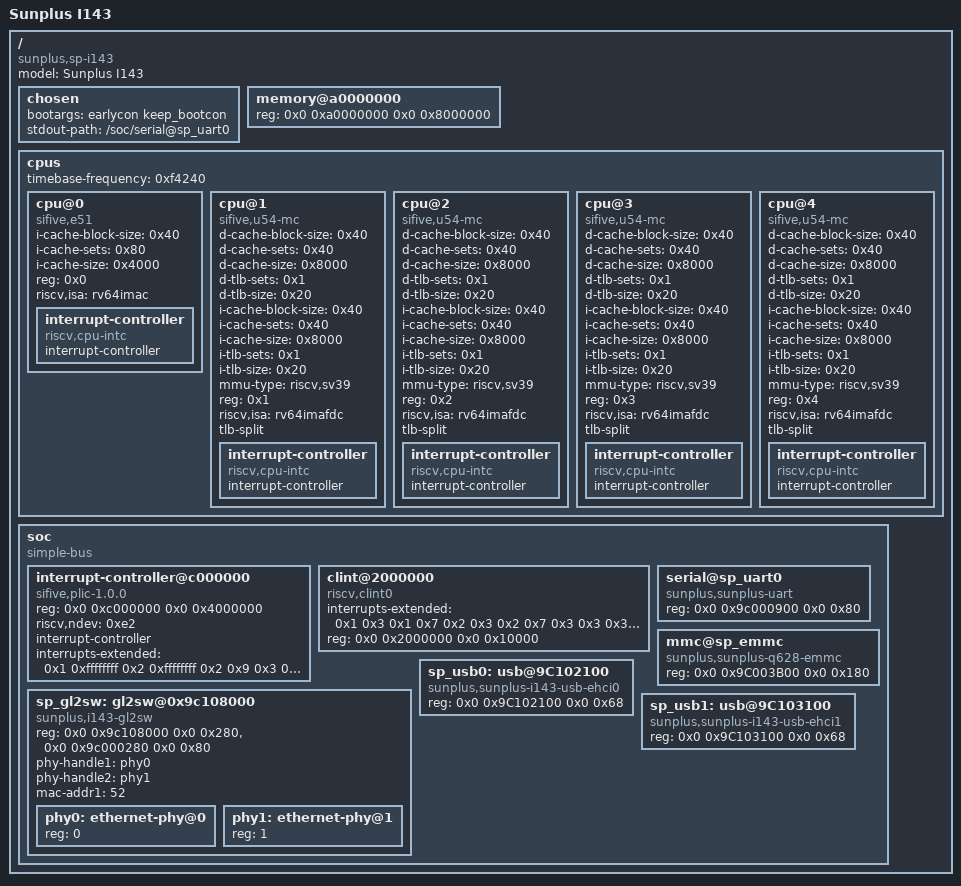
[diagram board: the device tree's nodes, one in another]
/dts-v1/;

/ {
	#address-cells = <0x2>;
	#size-cells = <0x2>;
	model = "Sunplus I143";
	compatible = "sunplus,sp-i143";

	chosen {
		bootargs = "earlycon keep_bootcon";
		stdout-path = "/soc/serial@sp_uart0";
	};

	memory@a0000000 {
		device_type = "memory";
		reg = <0x0 0xa0000000 0x0 0x8000000>;
	};

	cpus {
		timebase-frequency = <0xf4240>;
		#address-cells = <0x1>;
		#size-cells = <0x0>;

		cpu@0 {
			compatible = "sifive,e51", "sifive,rocket0", "riscv";
			device_type = "cpu";
			i-cache-block-size = <0x40>;
			i-cache-sets = <0x80>;
			i-cache-size = <0x4000>;
			reg = <0x0>;
			riscv,isa = "rv64imac";
			status = "okay";

			interrupt-controller {
				#interrupt-cells = <0x1>;
				compatible = "riscv,cpu-intc";
				interrupt-controller;
				phandle = <0x1>;
			};
		};

		cpu@1 {
			compatible = "sifive,u54-mc", "sifive,rocket0", "riscv";
			d-cache-block-size = <0x40>;
			d-cache-sets = <0x40>;
			d-cache-size = <0x8000>;
			d-tlb-sets = <0x1>;
			d-tlb-size = <0x20>;
			device_type = "cpu";
			i-cache-block-size = <0x40>;
			i-cache-sets = <0x40>;
			i-cache-size = <0x8000>;
			i-tlb-sets = <0x1>;
			i-tlb-size = <0x20>;
			mmu-type = "riscv,sv39";
			reg = <0x1>;
			riscv,isa = "rv64imafdc";
			tlb-split;
			status = "okay";

			interrupt-controller {
				#interrupt-cells = <0x1>;
				compatible = "riscv,cpu-intc";
				interrupt-controller;
				phandle = <0x2>;
			};
		};

		cpu@2 {
			compatible = "sifive,u54-mc", "sifive,rocket0", "riscv";
			d-cache-block-size = <0x40>;
			d-cache-sets = <0x40>;
			d-cache-size = <0x8000>;
			d-tlb-sets = <0x1>;
			d-tlb-size = <0x20>;
			device_type = "cpu";
			i-cache-block-size = <0x40>;
			i-cache-sets = <0x40>;
			i-cache-size = <0x8000>;
			i-tlb-sets = <0x1>;
			i-tlb-size = <0x20>;
			mmu-type = "riscv,sv39";
			reg = <0x2>;
			riscv,isa = "rv64imafdc";
			tlb-split;
			status = "okay";

			interrupt-controller {
				#interrupt-cells = <0x1>;
				compatible = "riscv,cpu-intc";
				interrupt-controller;
				phandle = <0x3>;
			};
		};

		cpu@3 {
			compatible = "sifive,u54-mc", "sifive,rocket0", "riscv";
			d-cache-block-size = <0x40>;
			d-cache-sets = <0x40>;
			d-cache-size = <0x8000>;
			d-tlb-sets = <0x1>;
			d-tlb-size = <0x20>;
			device_type = "cpu";
			i-cache-block-size = <0x40>;
			i-cache-sets = <0x40>;
			i-cache-size = <0x8000>;
			i-tlb-sets = <0x1>;
			i-tlb-size = <0x20>;
			mmu-type = "riscv,sv39";
			reg = <0x3>;
			riscv,isa = "rv64imafdc";
			tlb-split;
			status = "okay";

			interrupt-controller {
				#interrupt-cells = <0x1>;
				compatible = "riscv,cpu-intc";
				interrupt-controller;
				phandle = <0x4>;
			};
		};

		cpu@4 {
			compatible = "sifive,u54-mc", "sifive,rocket0", "riscv";
			d-cache-block-size = <0x40>;
			d-cache-sets = <0x40>;
			d-cache-size = <0x8000>;
			d-tlb-sets = <0x1>;
			d-tlb-size = <0x20>;
			device_type = "cpu";
			i-cache-block-size = <0x40>;
			i-cache-sets = <0x40>;
			i-cache-size = <0x8000>;
			i-tlb-sets = <0x1>;
			i-tlb-size = <0x20>;
			mmu-type = "riscv,sv39";
			reg = <0x4>;
			riscv,isa = "rv64imafdc";
			tlb-split;
			status = "okay";

			interrupt-controller {
				#interrupt-cells = <0x1>;
				compatible = "riscv,cpu-intc";
				interrupt-controller;
				phandle = <0x5>;
			};
		};
	};

	soc {
		#address-cells = <0x2>;
		#size-cells = <0x2>;
		compatible = "simple-bus";
		ranges;

		interrupt-controller@c000000 {
			#interrupt-cells = <0x1>;
			compatible = "sifive,plic-1.0.0";
			reg = <0x0 0xc000000 0x0 0x4000000>;
			riscv,ndev = <0xe2>;
			interrupt-controller;
			interrupts-extended = <0x1 0xffffffff 0x2 0xffffffff 0x2 0x9 0x3 0xffffffff 0x3 0x9 0x4 0xffffffff 0x4 0x9 0x5 0xffffffff 0x5 0x9>;
		};

		clint@2000000 {
			compatible = "riscv,clint0";
			interrupts-extended = <0x1 0x3 0x1 0x7 0x2 0x3 0x2 0x7 0x3 0x3 0x3 0x7 0x4 0x3 0x4 0x7 0x5 0x3 0x5 0x7>;
			reg = <0x0 0x2000000 0x0 0x10000>;
			reg-names = "control";
		};

		serial@sp_uart0 {
			compatible = "sunplus,sunplus-uart";
			reg = <0x0 0x9c000900 0x0 0x80>;
		};

		mmc@sp_emmc {
			compatible = "sunplus,sunplus-q628-emmc";
			reg = <0x0 0x9C003B00 0x0 0x180>;
		};

		sp_gl2sw: gl2sw@0x9c108000 {
			compatible = "sunplus,i143-gl2sw";
			reg = <0x0 0x9c108000 0x0 0x280>, <0x0 0x9c000280 0x0 0x80>;
			reg-names = "gl2sw", "moon5";
			phy-handle1 = <&phy0>;
			phy-handle2 = <&phy1>;
			mac-addr1 = <52>;
			#address-cells = <1>;
			#size-cells = <0>;
			phy0: ethernet-phy@0 {
				reg = <0>;
			};
			phy1: ethernet-phy@1 {
				reg = <1>;
			};
		};

		sp_usb0: usb@9C102100 {
			compatible = "sunplus,sunplus-i143-usb-ehci0";
			reg = <0x0 0x9C102100 0x0 0x68>;
		};

		sp_usb1: usb@9C103100 {
			compatible = "sunplus,sunplus-i143-usb-ehci1";
			reg = <0x0 0x9C103100 0x0 0x68>;
		};
	};
};
